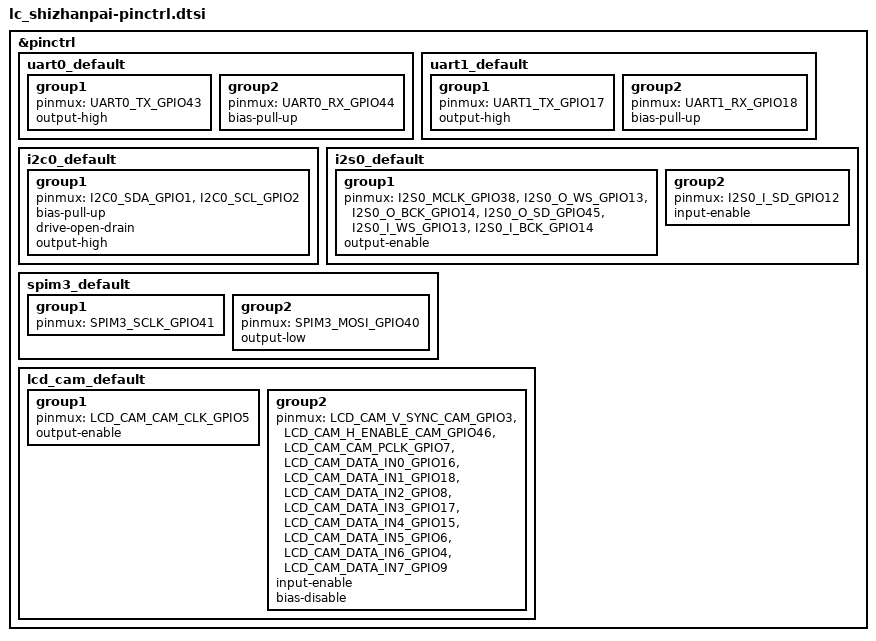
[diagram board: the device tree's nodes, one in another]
/*
 * Copyright (c) 2022 Espressif Systems (Shanghai) Co., Ltd.
 *
 * SPDX-License-Identifier: Apache-2.0
 */

#include <zephyr/dt-bindings/pinctrl/esp-pinctrl-common.h>
#include <dt-bindings/pinctrl/esp32s3-pinctrl.h>
#include <zephyr/dt-bindings/pinctrl/esp32s3-gpio-sigmap.h>

&pinctrl {
	uart0_default: uart0_default {
		group1 {
			pinmux = <UART0_TX_GPIO43>;
			output-high;
		};
		group2 {
			pinmux = <UART0_RX_GPIO44>;
			bias-pull-up;
		};
	};

	uart1_default: uart1_default {
		group1 {
			pinmux = <UART1_TX_GPIO17>;
			output-high;
		};
		group2 {
			pinmux = <UART1_RX_GPIO18>;
			bias-pull-up;
		};
	};

	i2c0_default: i2c0_default {
		group1 {
			pinmux = <I2C0_SDA_GPIO1>,
				<I2C0_SCL_GPIO2>;
			bias-pull-up;
			drive-open-drain;
			output-high;
		};
	};

	i2s0_default: i2s0_default {
		group1 {
			pinmux = <I2S0_MCLK_GPIO38>,
				<I2S0_O_WS_GPIO13>,
				<I2S0_O_BCK_GPIO14>,
				<I2S0_O_SD_GPIO45>,
				<I2S0_I_WS_GPIO13>,
				<I2S0_I_BCK_GPIO14>;
			output-enable;
		};
		group2 {
			pinmux = <I2S0_I_SD_GPIO12>;
			input-enable;
		};
	};

	spim3_default: spim3_default {
		group1 {
			pinmux = <SPIM3_SCLK_GPIO41>;
		};
		group2 {
			pinmux = <SPIM3_MOSI_GPIO40>;
			output-low;
		};
	};

	lcd_cam_default: lcd_cam_default{
		group1 {
			pinmux = <LCD_CAM_CAM_CLK_GPIO5>;
			output-enable;
		};
		group2 {
			pinmux = <LCD_CAM_V_SYNC_CAM_GPIO3>,
				<LCD_CAM_H_ENABLE_CAM_GPIO46>,
				<LCD_CAM_CAM_PCLK_GPIO7>,
				<LCD_CAM_DATA_IN0_GPIO16>,
				<LCD_CAM_DATA_IN1_GPIO18>,
				<LCD_CAM_DATA_IN2_GPIO8>,
				<LCD_CAM_DATA_IN3_GPIO17>,
				<LCD_CAM_DATA_IN4_GPIO15>,
				<LCD_CAM_DATA_IN5_GPIO6>,
				<LCD_CAM_DATA_IN6_GPIO4>,
				<LCD_CAM_DATA_IN7_GPIO9>;
			input-enable;
			bias-disable;
		};

	};
};
